# RTS5918 register map
Vendor: Realtek Semiconductor Corp.; Series: RTS5918 Series; File version: 1.00
CPU: ARMV8MML r0p0, little endian, MPU, FPU, VTOR, 3 interrupt priority bits, 8 SAU regions
Registers are 32-bit, read-write, reset 0x0 unless marked. A register's access mark holds for its fields unless they carry their own. Offsets are from the block's base; [hi:lo] are bit positions; {n}, {i} and the like mark numbered series.

## PECI — PECI Controller
Base 0x40221900
0x00 TX — TX DATA REGISTER
  [7:0] DATA — Tx data
0x04 RX ro — RX DATA REGISTER
  [7:0] DATA — Rx data
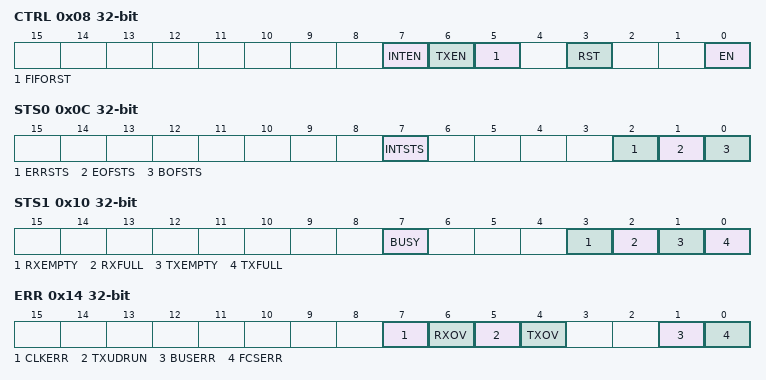
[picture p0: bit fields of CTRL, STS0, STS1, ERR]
0x08 CTRL — CONTROL REGISTER
  [7] INTEN — Enable PECI Interrupt
    0=DISABLE (Disable PECI interrupt); 1=ENABLE (Enable PECI interrupt)
  [6] TXEN — Enable PECI Tx
    0=DISABLE (Disable PECI Tx); 1=ENABLE (Enable PECI Tx)
  [5] FIFORST — Reset PECI FIFO
    0=DO_NOTHING; 1=RESET (Reset PECI FIFO)
  [3] RST — Reset PECI Contoller
    0=DO_NOTHING; 1=RESET (Reset PECI contoller)
  [0] EN — Enable PECI Contoller
    0=DISABLE (Disable PECI controller); 1=ENABLE (Enable PECI controller)
0x0C STS0 — STATUS REGISTER #0
  [7] INTSTS ro — Interrupt Status
    0=NOT_OCCURRED (Interrupt is not occurred); 1=OCCURRED (Interrupt is occurred)
  [2] ERRSTS ro — Error Status
    0=NOT_OCCURRED (Error is not occurred); 1=OCCURRED (Error is occurred)
  [1] EOFSTS write-1-clears — End of Frame Status
    0=NOT_OCCURRED (End of Frame is not occurred); 1=OCCURRED (End of Frame is occurred)
  [0] BOFSTS write-1-clears — Begin of Frame Status
    0=NOT_OCCURRED (Beginning of Frame is not occurred); 1=OCCURRED (Beginning of Frame is occurred)
0x10 STS1 ro — STATUS REGISTER #1
  [7] BUSY — PECI is busy
  [3] RXEMPTY — Rx FIFO is Empty
  [2] RXFULL — Rx FIFO is Full
  [1] TXEMPTY — Tx FIFO is Empty
  [0] TXFULL — Tx FIFO is Full
0x14 ERR — ERROR REGISTER
  [7] CLKERR — Error State of Unnormal PECI Clock
  [6] RXOV — Rx Buffer Overflow
  [5] TXUDRUN — Tx Buffer Underrun
  [4] TXOV — Tx Buffer Overflow
  [1] BUSERR — Bus Error
  [0] FCSERR — FCS Error
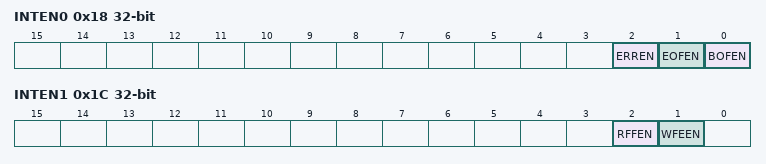
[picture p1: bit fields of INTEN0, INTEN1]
0x18 INTEN0 — INTERRUPT ENABLE REGISTER #0
  [2] ERREN — Enable ERR Interrupt
    0=DISABLE (Disabled ERR interrupt); 1=ENABLE (Enable ERR interrupt)
  [1] EOFEN — Enable EOF Interrupt
    0=DISABLE (Disabled EOF interrupt); 1=ENABLE (Enable EOF interrupt)
  [0] BOFEN — Enable BOF Interrupt
    0=DISABLE (Disabled BOF interrupt); 1=ENABLE (Enable BOF interrupt)
0x1C INTEN1 — INTERRUPT ENABLE REGISTER #1
  [2] RFFEN — Enable RFF Interrupt
    0=DISABLE (Disabled RFF interrupt); 1=ENABLE (Enable RFF interrupt)
  [1] WFEEN — Enable WFE Interrupt
    0=DISABLE (Disabled WFE interrupt); 1=ENABLE (Enable WFE interrupt)
0x20 OBTL — OPTIMAL BIT TIME REGISTER LOW
  [7:0] VAL — Bit time low value
0x24 OBTH — OPTIMAL BIT TIME REGISTER HIGH
  [7:0] VAL — Bit time high value
0x48 CTRL1 — PECI CONTROL 1 REGISTER
  [7] DM — Drive Mode

## KBC — KBC Controller
Base 0x40221700
Same registers: PMPORT0 0x400A021C, PMPORT1 0x400A0238, PMPORT2 0x400A0254, PMPORT3 0x400A0270
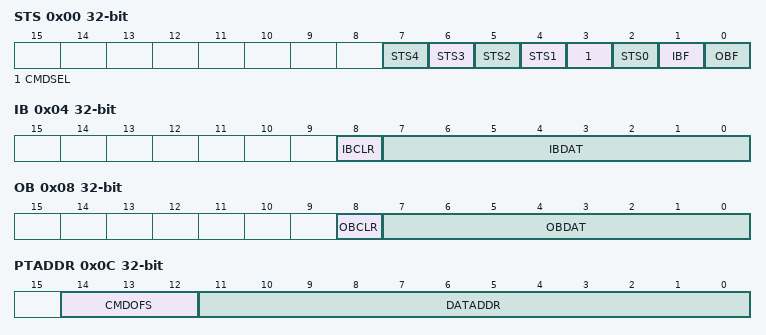
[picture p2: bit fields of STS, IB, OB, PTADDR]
0x00 STS — STATUS REGISTER
  [n+3] STS{n} (n=1..4) — Genral Purpose Status #{n}
  [3] CMDSEL ro — Command or Data Seletion
    0=DATA_PORT (Master write into data port); 1=CMD_PORT (Master write into command port)
  [2] STS0 — Genral Purpose Status #0
  [1] IBF ro — Iutput Buffer Full Status
    0=NOT_FULL (Iutput buffer is not full); 1=FULL (Iutput buffer is full)
  [0] OBF ro — Output Buffer Full Status
    0=NOT_FULL (Output buffer is not full); 1=FULL (Output buffer is full)
0x04 IB — INPUT BUFFER REGISTER
  [8] IBCLR write-1-clears — Input Buffer Clear
    0=DO_NOTHING; 1=CLEAR (Clear input buffer)
  [7:0] IBDAT — Inpurt Buffer Data
0x08 OB — OUTPUT BUFFER REGISTER
  [8] OBCLR write-1-clears — Output Buffer Clear
    0=DO_NOTHING; 1=CLEAR (Clear input buffer)
  [7:0] OBDAT — Output Buffer Data
0x0C PTADDR — PORT ADDRESS REGISTER
  [14:12] CMDOFS — Comand Port Offset
  [11:0] DATADDR — Data Port Address
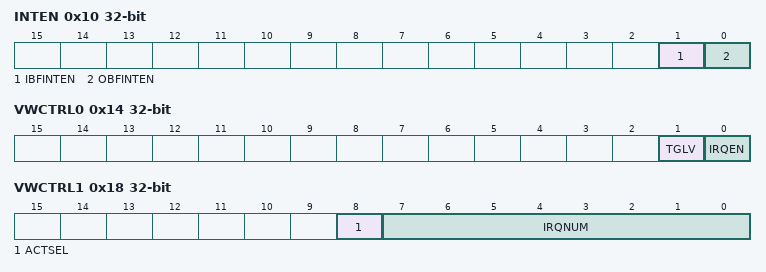
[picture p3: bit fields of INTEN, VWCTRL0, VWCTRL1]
0x10 INTEN — INTERRUPT ENABLE REGISTER
  [1] IBFINTEN — Iutput Buffer Interrupt Enable
    0=DISABLE (Disabled input buffer interrupt); 1=ENABLE (Enable input buffer interrupt)
  [0] OBFINTEN — Output Buffer Interrupt Enable
    0=DISABLE (Disabled output buffer interrupt); 1=ENABLE (Enable output buffer interrupt)
0x14 VWCTRL0 — VIRTUAL WIRE CONTROL REGISTER #0
  [1] TGLV — Trigger Level Select
    0=LOW (Low level trigger select); 1=HIGH (High level trigger select)
  [0] IRQEN — Auto IRQ Enable
    0=DISABLE (Disabled auto IRQ); 1=ENABLE (Enable auto IRQ)
0x18 VWCTRL1 — VIRTUAL WIRE CONTROL REGISTER #1
  [8] ACTSEL — Activate Enable
    0=DISABLE (Disable activate); 1=ENABLE (Enable activate)
  [7:0] IRQNUM — IRQ Number

## ACPI — ACPI Controller
Base 0x40221400
Registers as KBC; these are added or differ:
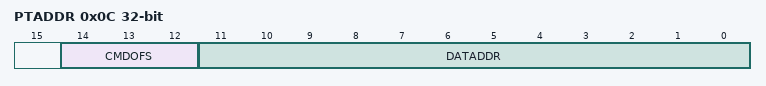
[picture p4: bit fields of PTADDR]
0x0C PTADDR — PORT ADDRESS REGISTER
  [14:12] CMDOFS — Coomand Port Offset
  [11:0] DATADDR — Data Port Address
